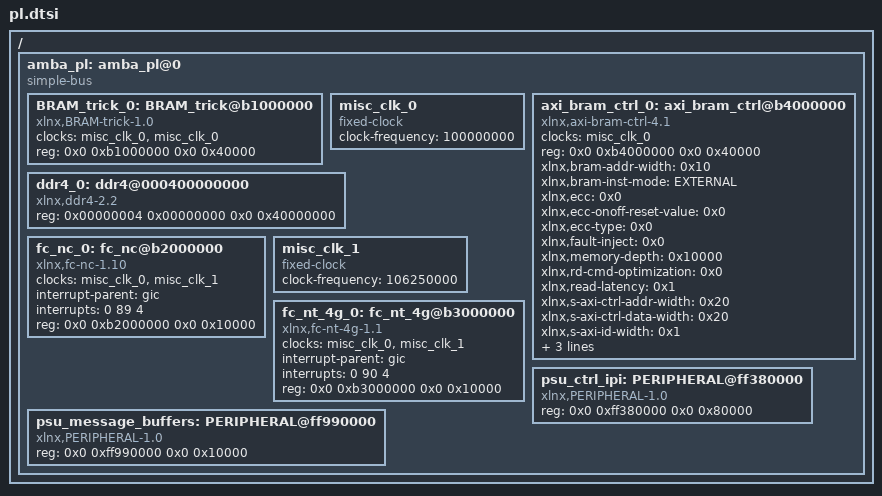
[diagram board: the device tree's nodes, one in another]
/*
 * CAUTION: This file is automatically generated by Xilinx.
 * Version:  
 * Today is: Mon Jan 25 11:18:51 2021
 */


/ {
	amba_pl: amba_pl@0 {
		#address-cells = <2>;
		#size-cells = <2>;
		compatible = "simple-bus";
		ranges ;
		BRAM_trick_0: BRAM_trick@b1000000 {
			clock-names = "BRAM_CTRL_S_AXI_ACLK", "BRAM_CTRL_M_AXI_ACLK";
			clocks = <&misc_clk_0>, <&misc_clk_0>;
			compatible = "xlnx,BRAM-trick-1.0";
			reg = <0x0 0xb1000000 0x0 0x40000>;
		};
		misc_clk_0: misc_clk_0 {
			#clock-cells = <0>;
			clock-frequency = <100000000>;
			compatible = "fixed-clock";
		};
		axi_bram_ctrl_0: axi_bram_ctrl@b4000000 {
			clock-names = "s_axi_aclk";
			clocks = <&misc_clk_0>;
			compatible = "xlnx,axi-bram-ctrl-4.1";
			reg = <0x0 0xb4000000 0x0 0x40000>;
			xlnx,bram-addr-width = <0x10>;
			xlnx,bram-inst-mode = "EXTERNAL";
			xlnx,ecc = <0x0>;
			xlnx,ecc-onoff-reset-value = <0x0>;
			xlnx,ecc-type = <0x0>;
			xlnx,fault-inject = <0x0>;
			xlnx,memory-depth = <0x10000>;
			xlnx,rd-cmd-optimization = <0x0>;
			xlnx,read-latency = <0x1>;
			xlnx,s-axi-ctrl-addr-width = <0x20>;
			xlnx,s-axi-ctrl-data-width = <0x20>;
			xlnx,s-axi-id-width = <0x1>;
			xlnx,s-axi-supports-narrow-burst = <0x1>;
			xlnx,select-xpm = <0x1>;
			xlnx,single-port-bram = <0x0>;
		};
		ddr4_0: ddr4@000400000000 {
			compatible = "xlnx,ddr4-2.2";
			reg = <0x00000004 0x00000000 0x0 0x40000000>;
		};
		fc_nc_0: fc_nc@b2000000 {
			clock-names = "FC_NC_ACLK", "mgt_refclk";
			clocks = <&misc_clk_0>, <&misc_clk_1>;
			compatible = "xlnx,fc-nc-1.10";
			interrupt-names = "COP_Intr";
			interrupt-parent = <&gic>;
			interrupts = <0 89 4>;
			reg = <0x0 0xb2000000 0x0 0x10000>;
		};
		misc_clk_1: misc_clk_1 {
			#clock-cells = <0>;
			clock-frequency = <106250000>;
			compatible = "fixed-clock";
		};
		fc_nt_4g_0: fc_nt_4g@b3000000 {
			clock-names = "FC_NT_S_AXI_CLK", "mgt_refclk_i";
			clocks = <&misc_clk_0>, <&misc_clk_1>;
			compatible = "xlnx,fc-nt-4g-1.1";
			interrupt-names = "thre_int_o";
			interrupt-parent = <&gic>;
			interrupts = <0 90 4>;
			reg = <0x0 0xb3000000 0x0 0x10000>;
		};
		psu_ctrl_ipi: PERIPHERAL@ff380000 {
			compatible = "xlnx,PERIPHERAL-1.0";
			reg = <0x0 0xff380000 0x0 0x80000>;
		};
		psu_message_buffers: PERIPHERAL@ff990000 {
			compatible = "xlnx,PERIPHERAL-1.0";
			reg = <0x0 0xff990000 0x0 0x10000>;
		};
	};
};
